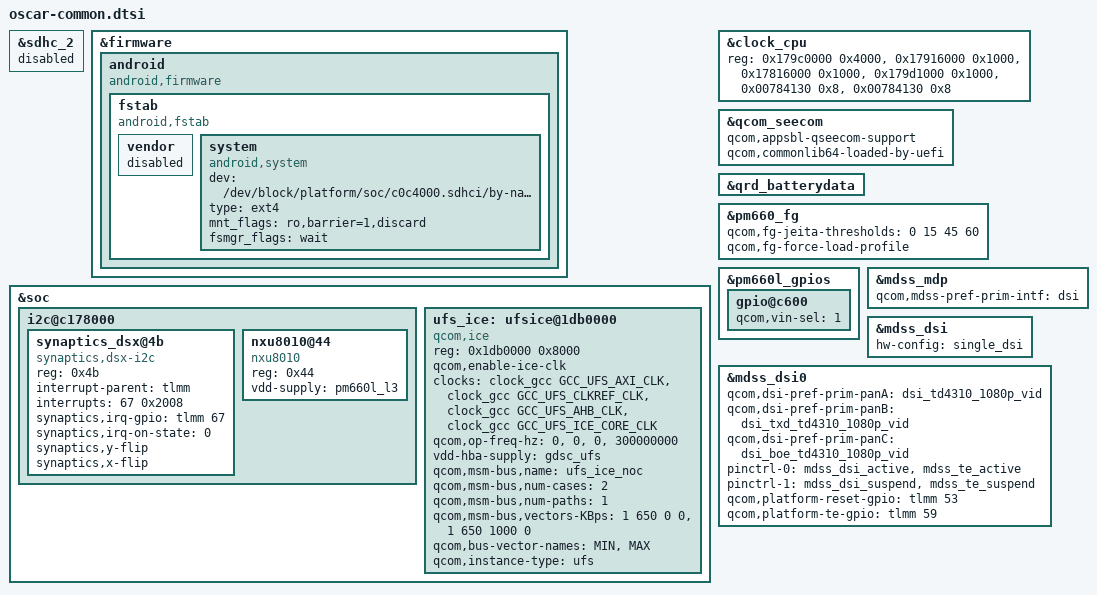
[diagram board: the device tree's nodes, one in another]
/*
 * Copyright (c) 2017, The Linux Foundation. All rights reserved.
 *
 * This program is free software; you can redistribute it and/or modify
 * it under the terms of the GNU General Public License version 2 and
 * only version 2 as published by the Free Software Foundation.
 *
 * This program is distributed in the hope that it will be useful,
 * but WITHOUT ANY WARRANTY; without even the implied warranty of
 * MERCHANTABILITY or FITNESS FOR A PARTICULAR PURPOSE.  See the
 * GNU General Public License for more details.
 */

&sdhc_2 {
	status = "disabled";
};

&firmware {
	android {
		compatible = "android,firmware";
		fstab {
			compatible = "android,fstab";

			vendor {
				status = "disabled";
			};

			system {
				compatible = "android,system";
				dev = "/dev/block/platform/soc/c0c4000.sdhci/by-name/system";
				type = "ext4";
				mnt_flags = "ro,barrier=1,discard";
				fsmgr_flags = "wait";
				status = "ok";
			};
		};
	};
};

&soc {
	i2c@c178000 { /* BLSP1 QUP3 */
		status = "okay";
		synaptics_dsx@4b {
			compatible = "synaptics,dsx-i2c";
			reg = <0x4b>;
			interrupt-parent = <&tlmm>;
			interrupts = <67 0x2008>;
			synaptics,irq-gpio = <&tlmm 67 0x2008>; /* IRQF_ONESHOT | IRQF_TRIGGER_LOW */
			synaptics,irq-on-state = <0>;
			synaptics,y-flip;
			synaptics,x-flip;
		};

		nxu8010@44 {
			compatible = "nxu8010";
			reg = <0x44>;
			vdd-supply = <&pm660l_l3>;
		};
	};

	ufs_ice: ufsice@1db0000 {
		compatible = "qcom,ice";
		reg = <0x1db0000 0x8000>;
		qcom,enable-ice-clk;
		clock-names =
			"ufs_core_clk",
			"bus_clk",
			"iface_clk",
			"ice_core_clk";
		clocks =
			<&clock_gcc GCC_UFS_AXI_CLK>,
			<&clock_gcc GCC_UFS_CLKREF_CLK>,
			<&clock_gcc GCC_UFS_AHB_CLK>,
			<&clock_gcc GCC_UFS_ICE_CORE_CLK>;
		qcom,op-freq-hz = <0>, <0>, <0>, <300000000>;
		vdd-hba-supply = <&gdsc_ufs>;
		qcom,msm-bus,name = "ufs_ice_noc";
		qcom,msm-bus,num-cases = <2>;
		qcom,msm-bus,num-paths = <1>;
		qcom,msm-bus,vectors-KBps =
				<1 650 0 0>,    /* No vote */
				<1 650 1000 0>; /* Max. bandwidth */
		qcom,bus-vector-names = "MIN",
					"MAX";
		qcom,instance-type = "ufs";
	};
};

&clock_cpu {
	reg = <0x179c0000 0x4000>, <0x17916000 0x1000>,
	      <0x17816000 0x1000>, <0x179d1000 0x1000>,
	      <0x00784130 0x8>, <0x00784130 0x8>;
	reg-names = "osm", "pwrcl_pll", "perfcl_pll",
		    "apcs_common", "pwrcl_efuse",
		    "perfcl_efuse";

	/delete-property/ qcom,pc-override-index;
};

&qcom_seecom {
	qcom,appsbl-qseecom-support;
	qcom,commonlib64-loaded-by-uefi;
};

&qrd_batterydata {
	#include "fg-gen3-batterydata-oscar-atl-3500mah.dtsi"
	#include "fg-gen3-batterydata-oscar-scud-3500mah.dtsi"
};

&pm660_fg {
	qcom,fg-jeita-thresholds = <0 15 45 60>;
	qcom,fg-force-load-profile;
};

&pm660l_gpios {
	gpio@c600 {
		qcom,vin-sel = <1>;
	};
};

&mdss_mdp {
	qcom,mdss-pref-prim-intf = "dsi";
};

&mdss_dsi {
	hw-config = "single_dsi";
};

&mdss_dsi0 {
	qcom,dsi-pref-prim-panA = <&dsi_td4310_1080p_vid>;
	qcom,dsi-pref-prim-panB = <&dsi_txd_td4310_1080p_vid>;
	qcom,dsi-pref-prim-panC = <&dsi_boe_td4310_1080p_vid>;
	pinctrl-names = "mdss_default", "mdss_sleep";
	pinctrl-0 = <&mdss_dsi_active &mdss_te_active>;
	pinctrl-1 = <&mdss_dsi_suspend &mdss_te_suspend>;
	qcom,platform-reset-gpio = <&tlmm 53 0>;
	qcom,platform-te-gpio = <&tlmm 59 0>;
};
